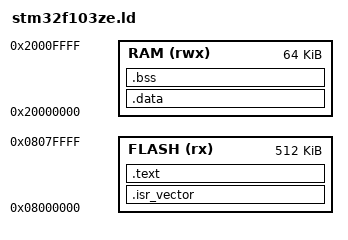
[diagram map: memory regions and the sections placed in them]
MEMORY
{
  FLASH (rx) : ORIGIN = 0x08000000, LENGTH = 512K
  RAM (rwx)  : ORIGIN = 0x20000000, LENGTH = 64K
}

_estack = ORIGIN(RAM) + LENGTH(RAM);

SECTIONS
{
  .isr_vector :
  {
    KEEP(*(.isr_vector))
  } > FLASH

  .text :
  {
    *(.text*)
    *(.rodata*)
    . = ALIGN(4);
    _etext = .;
  } > FLASH

  .data : AT(_etext)
  {
    _sdata = .;
    *(.data*)
    . = ALIGN(4);
    _edata = .;
  } > RAM
  _sidata = LOADADDR(.data);

  .bss :
  {
    _sbss = .;
    *(.bss*)
    *(COMMON)
    . = ALIGN(4);
    _ebss = .;
  } > RAM
}
